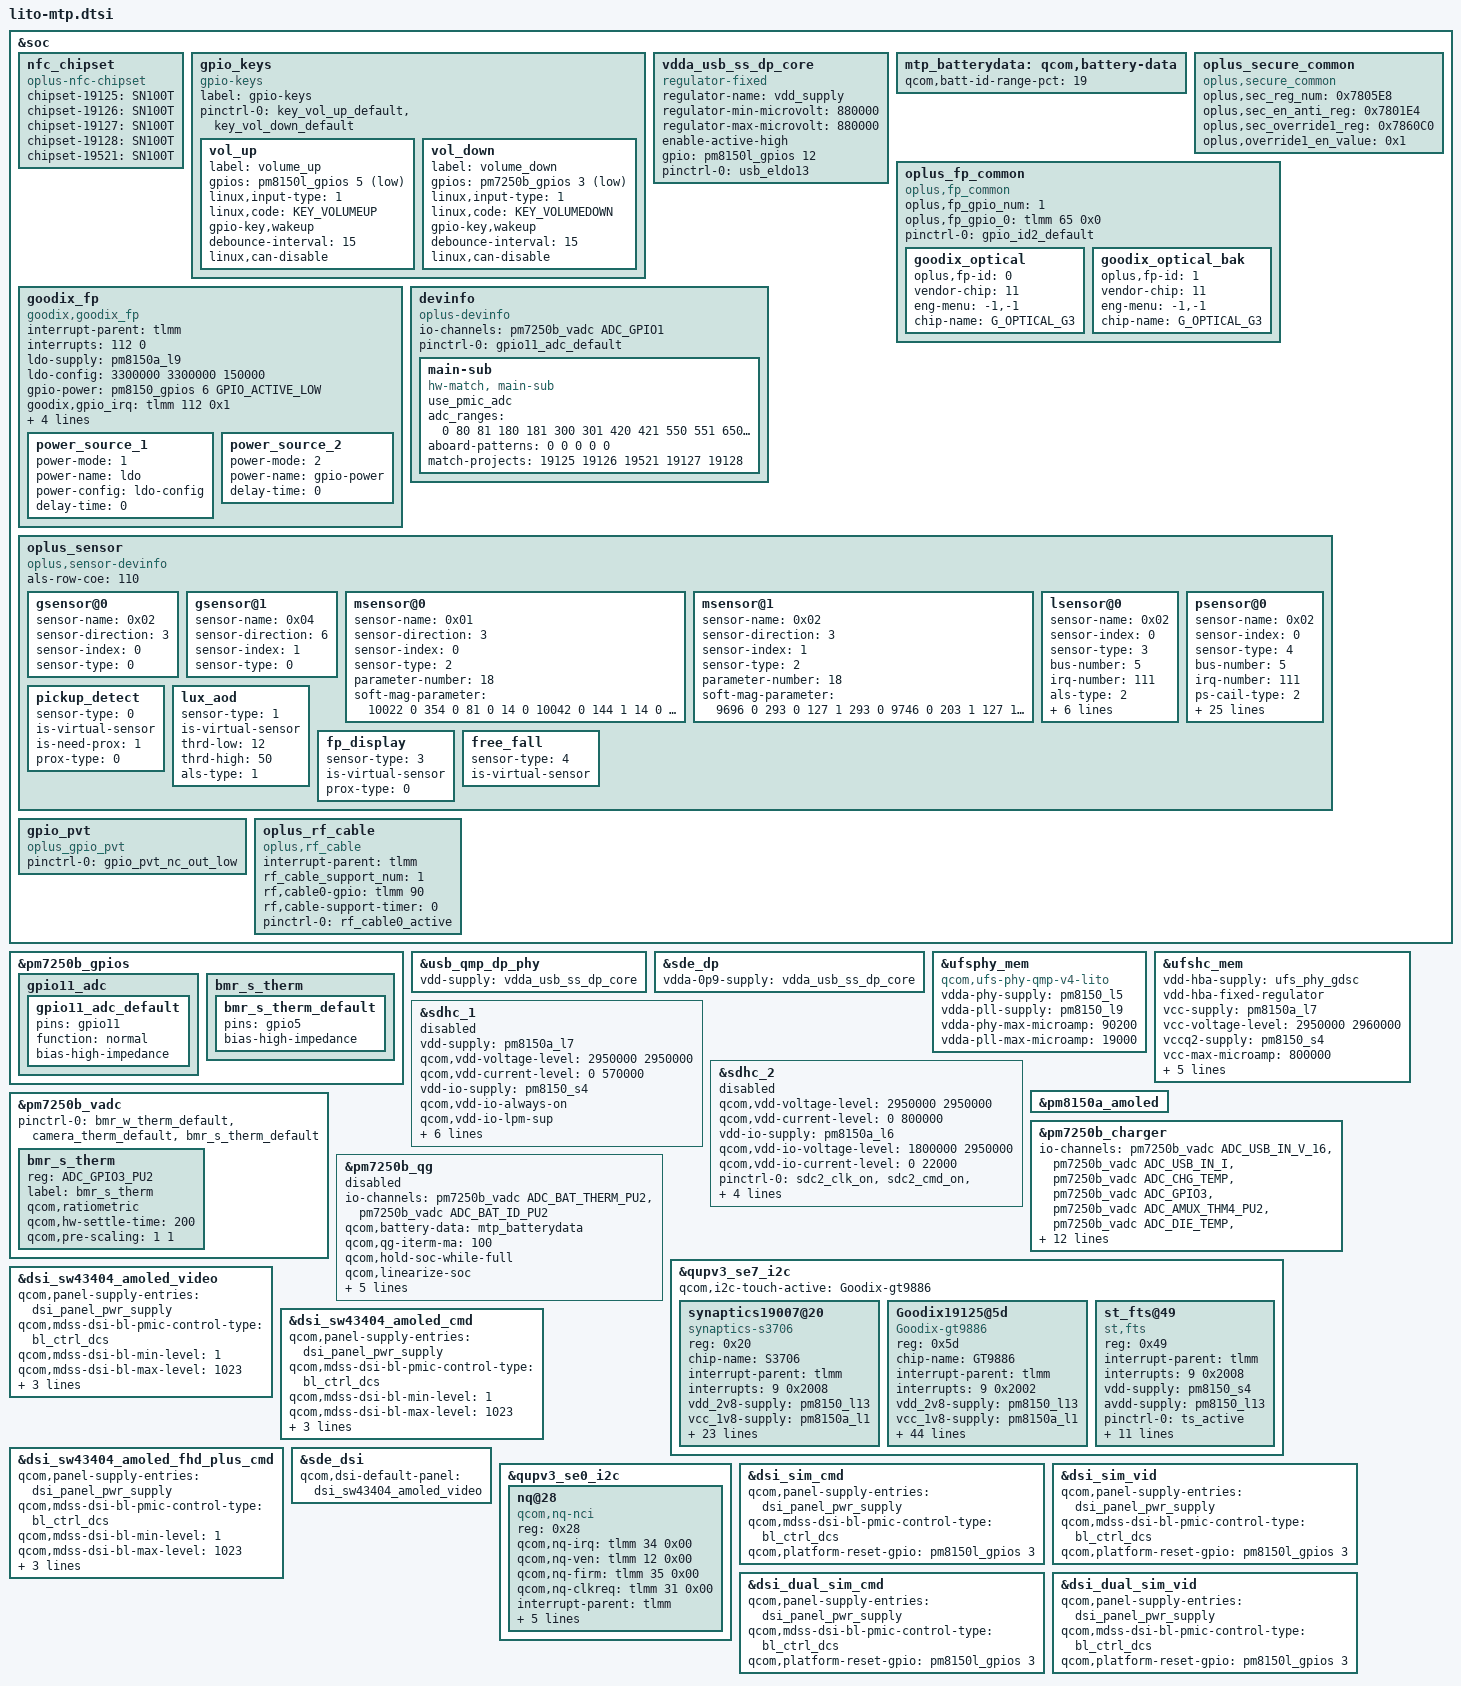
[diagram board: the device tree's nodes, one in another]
#include <dt-bindings/gpio/gpio.h>
#include "lito-audio-overlay.dtsi"
#include "lito-pmic-overlay.dtsi"
#include "camera/lito-camera-sensor-mtp.dtsi"
#include "lito-sde-display.dtsi"
#include "lito-thermal-overlay.dtsi"
#include "oplus_charge.dtsi"

&soc {
	//#ifdef OPLUS_FEATURE_CONNFCSOFT
	nfc_chipset {
		compatible = "oplus-nfc-chipset";
		chipset-19125 = "SN100T";
		chipset-19126 = "SN100T";
		chipset-19127 = "SN100T";
		chipset-19128 = "SN100T";
		chipset-19521 = "SN100T";
	};
	//#endif /* OPLUS_FEATURE_CONNFCSOFT */

	gpio_keys {
		compatible = "gpio-keys";
		label = "gpio-keys";

		pinctrl-names = "default";
		//#ifdef OPLUS_FEATURE_TP_BSPFWUPDATE
		pinctrl-0 = <&key_vol_up_default &key_vol_down_default>;
		//#endif

		vol_up {
			label = "volume_up";
			gpios = <&pm8150l_gpios 5 GPIO_ACTIVE_LOW>;
			linux,input-type = <1>;
			linux,code = <KEY_VOLUMEUP>;
			gpio-key,wakeup;
			debounce-interval = <15>;
			linux,can-disable;
		};
		//#ifdef OPLUS_FEATURE_TP_BSPFWUPDATE
		vol_down {
			label = "volume_down";
			gpios = <&pm7250b_gpios  3 GPIO_ACTIVE_LOW>;
			linux,input-type = <1>;
			linux,code = <KEY_VOLUMEDOWN>;
			gpio-key,wakeup;
			debounce-interval = <15>;
			linux,can-disable;
		};
		//#endif
	};

	vdda_usb_ss_dp_core: vdda_usb_ss_dp_core {
		compatible = "regulator-fixed";
		regulator-name = "vdd_supply";
		regulator-min-microvolt = <880000>;
		regulator-max-microvolt = <880000>;
		enable-active-high;
		gpio = <&pm8150l_gpios 12 GPIO_ACTIVE_HIGH>;
		pinctrl-names = "default";
		pinctrl-0 = <&usb_eldo13>;
	};

	mtp_batterydata: qcom,battery-data {
//#ifndef OPLUS_FEATURE_CHG_BASIC
//		qcom,batt-id-range-pct = <15>;
//#else
        qcom,batt-id-range-pct = <19>;
//#endif
		#include "qg-batterydata-alium-3600mah.dtsi"
		#include "qg-batterydata-atl466271_3300mAh.dtsi"
	};

	// #ifdef OPLUS_FEATURE_SECURITY_COMMON
	oplus_secure_common {
		compatible = "oplus,secure_common";
		oplus,sec_reg_num = <0x7805E8>;
		oplus,sec_en_anti_reg = <0x7801E4>;
		oplus,sec_override1_reg = <0x7860C0>;
		oplus,override1_en_value = <0x1>;
	};
	//#endif /* OPLUS_FEATURE_SECURITY_COMMON */

	//#ifdef OPLUS_FEATURE_FINGERPRINT
	oplus_fp_common {
		compatible = "oplus,fp_common";
		oplus,fp_gpio_num = <1>; /* the gpio number of fingerprint id used */
		oplus,fp_gpio_0 = <&tlmm 65 0x0>;
		pinctrl-names = "default";
		pinctrl-0 = <&gpio_id2_default>;
		goodix_optical {
			oplus,fp-id = <0>; /* fp id mapping table */
			vendor-chip = <11>; /* please refer to the struct fp_vendor_t in oplus_fp_commmon.n */
			eng-menu = "-1,-1"; /* represents SNR, inclination test item in engineer menu, and 0/1 means off/on */
			chip-name = "G_OPTICAL_G3";  /* /proc/fp_id, will be displayed in engineer menu  */
		};
		goodix_optical_bak {
			oplus,fp-id = <1>; /* fp id mapping table */
			vendor-chip = <11>; /* please refer to the struct fp_vendor_t in oplus_fp_commmon.n */
			eng-menu = "-1,-1"; /* represents SNR, inclination test item in engineer menu, and 0/1 means off/on */
			chip-name = "G_OPTICAL_G3";  /* /proc/fp_id, will be displayed in engineer menu  */
		};
	};

	goodix_fp {
		status = "ok";
		compatible = "goodix,goodix_fp";
		interrupt-parent = <&tlmm>;
		interrupts = <112 0>;

		ldo-supply = <&pm8150a_l9>; // pm660l_l5 for goodix_fp
		ldo-config = <3300000 3300000 150000>;

		gpio-power = <&pm8150_gpios 6 GPIO_ACTIVE_LOW>;
		goodix,gpio_irq = <&tlmm 112 0x1>;
		goodix,gpio_reset = <&tlmm 63 0x0>;
		pinctrl-names = "default";
		pinctrl-0 = <&gpio_goodix_irq_default>;
		pinctrl-1 = <&goodix_pwr_default>;

		power-num = <2> ;
		power_source_1 {
			power-mode = <1>;   /* 1 = ldo power, refer to oplus_fp_common.h*/
			power-name = "ldo";
			power-config = "ldo-config";
			delay-time = <0>;
		};
		power_source_2 {
			power-mode = <2>;   /* 2 = gpio power, refer to oplus_fp_common.h */
			power-name = "gpio-power";
			delay-time = <0>;
		};
	};
	//#endif /*OPLUS_FEATURE_FINGERPRINT*/

//#ifdef OPLUS_ARCH_EXTENDS
	devinfo {
	compatible = "oplus-devinfo";

	io-channels= <&pm7250b_vadc ADC_GPIO1>;
	io-channel-names= "vph_pwr_voltage_sub";
	pinctrl-names = "default";
	pinctrl-0 = <&gpio11_adc_default>;

	main-sub {
		compatible = "hw-match, main-sub";
		use_pmic_adc;
		adc_ranges = <0 80
					81 180
					181 300
					301 420
					421 550
					551 650
					651 760
					761 850
					851 850
					951 1050
					1051 1150
					1151 1300>;
		aboard-patterns = <0 0 0 0 0>;

		/*main board*/
		match-projects = <19125 19126 19521 19127 19128>;
		};
	};
//#endif /*OPLUS_ARCH_EXTENDS*/

	//#ifdef OPLUS_FEATURE_SENSOR_SMEM
	/*enum sensor_id { ACCEL,GYRO,MAG,LIGHT,PROXIMITY,SAR,CT,BAROMETER,SENSORS_NUM};*/
	oplus_sensor {
		compatible = "oplus,sensor-devinfo";
		als-row-coe = <110>;
		/*enum {LSM6DSM = 0x01, BMI160 = 0x02, LSM6DS3 = 0x04};*/
		gsensor@0 {
			sensor-name = <0x02>;//BMI160
			sensor-direction = <3>;
			sensor-index = <0>;//source num
			sensor-type = <0>;//ACCEL
		};
		gsensor@1 {
			sensor-name = <0x04>;//LSM6DS3
			sensor-direction = <6>;
			sensor-index = <1>;//source num
			sensor-type = <0>;//ACCEL
		};
		/* enum {AKM0991X = 0x01, MMC5603 = 0x02};*/
		msensor@0 {
			sensor-name = <0x01>;//AKM09918
			sensor-direction = <3>;
			sensor-index = <0>;
			sensor-type = <2>;//MAG
			parameter-number= <18>;
			soft-mag-parameter = <10022 0 354 0 81 0 14 0 10042 0 144 1 14 0 234 1 10250 0>;//e00 sign e01 sign...
		};
		msensor@1 {
			sensor-name = <0x02>;//MMC5603
			sensor-direction = <3>;
			sensor-index = <1>;
			sensor-type = <2>;//MAG
			parameter-number= <18>;
			soft-mag-parameter = <9696 0 293 0 127 1 293 0 9746 0 203 1 127 1 203 1 10600 0>;//e00 sign e01 sign...
		};
		/*enum {STK3A5X=0x01,TCS3701=0x02,TCS3408=0x04,STK3A6X=0x08};*/
		/*enum {NORMAL=0x01,UNDER_LCD=0x02,VIRTUAL_UNDER_LCD=0x03}*/
		lsensor@0 {
			sensor-name = <0x02>;//TCS3701
			sensor-index = <0>;
			sensor-type = <3>;//LIGHT
			bus-number = <5>;
			irq-number = <111>;
			als-type = <2>;
			is-unit-device = <1>;
			is-als-dri = <1>;
			als-factor = <110>;
			is_als_initialed = <0>;
			als_buffer_length = <10>;
			normalization_value = <549>;
		};
		psensor@0 {
			sensor-name = <0x02>;//TCS3701
			sensor-index = <0>;
			sensor-type = <4>;//PROXIMITY
			bus-number = <5>;
			irq-number = <111>;
			ps-cail-type = <2>;
			ps-type = <1>;
			is_ps_initialzed = <0>;
			low_step = <300>;//ps_low_thd_incr
			high_step = <400>;//ps_high_thd_incr
			low_limit = <400>;//ps_low_thd_max
			high_limit = <600>;//ps_high_thd_max
			dirty_low_step = <180>;//dirty_low_thd_incr
			dirty_high_step = <250>;//dirty_high_thd_incr
			ps_dirty_limit = <1022>;//dirty_limit
			ps_ir_limit = <500>;//ir_jam_limit
			ps_adjust_min = <0>;//ps_adjust_min
			ps_adjust_max = <600>;//ps_adjust_max
			sampling_count = <5>;//sampling_count
			step_max = <400>;//incr_max
			step_min = <110>;//incr_min
			step_div = <1500>;//cali_div
			anti_shake_delta = <80>;//delta
			dynamic_cali_max = <1024>;//dynamic_cali_max
			raw2offset_radio = <20800>;//raw_to_offser_radio
			offset_max = <250>;//max_offset
			offset_range_min = <0xFFFFFF01>;//-255
			offset_range_max = <255>;
			force_cali_limit = <2000>;
			cali_jitter_limit = <30>;//dynamic_cali_value
			cal_offset_margin = <120>;//cal_offset_margin
		};
		/*virtual sensor
		enum sensor_algo_id {
			PICKUP_DETECT,
			LUX_AOD,
			TP_GESTURE,
			FP_DISPLAY,
			FREE_FALL,
			CAMERA_PROTECT,
			SENSOR_ALGO_NUM
		}*/
		pickup_detect {
			sensor-type = <0>; //PICKUP_DETECT
			is-virtual-sensor;
			is-need-prox = <1>;
			prox-type = <0>; // 0 - proximity; 1 - proximity_fake
		};
		lux_aod {
			sensor-type = <1>; //LUX_AOD
			is-virtual-sensor;
			thrd-low = <12>;
			thrd-high = <50>;
			als-type = <1>; // 0 - ambient_light; 1 - wise_light
		};
		fp_display {
			sensor-type = <3>; //FP_DISPLAY
			is-virtual-sensor;
			prox-type = <0>; // 0 - proximity; 1 - proximity_fake
		};
		free_fall {
			sensor-type = <4>; //FREE_FALL
			is-virtual-sensor;
		};
	};
	//#endif /*OPLUS_FEATURE_SENSOR_SMEM*/

	gpio_pvt {
		status = "ok";
		compatible = "oplus_gpio_pvt";
		pinctrl-names = "default";
		pinctrl-0 = <&gpio_pvt_nc_out_low>;
	};
	//#endif

        //#ifdef OPLUS_ARCH_EXTENDS
	oplus_rf_cable {
		compatible = "oplus,rf_cable";
		interrupt-parent = <&tlmm>;
		rf_cable_support_num = <1>;
		rf,cable0-gpio = <&tlmm 90 0>;
		rf,cable-support-timer = <0>;
		pinctrl-names = "rf_cable_active";
		pinctrl-0 = <&rf_cable0_active>;
	};
	//#endif /* OPLUS_ARCH_EXTENDS */
};

//#ifndef OPLUS_FEATURE_CHG_BASIC
//&usb2_phy0 {
//	qcom,param-override-seq = <0xa1 0x6c
//				0x43 0x70>;
//};
//#endif
//#ifdef OPLUS_FEATURE_CHG_BASIC
&pm7250b_gpios{
	gpio11_adc {
        gpio11_adc_default: gpio11_adc_default {
        pins = "gpio11"; /* GPIO 11 */
        function = "normal"; /* normal */
        bias-high-impedance; /* DISABLE GPIO11 for ADC*/
        };
    };
};
//#endif

&usb_qmp_dp_phy {
	vdd-supply = <&vdda_usb_ss_dp_core>;
};

&sde_dp {
	vdda-0p9-supply = <&vdda_usb_ss_dp_core>;
};

&ufsphy_mem {
	compatible = "qcom,ufs-phy-qmp-v4-lito";

	vdda-phy-supply = <&pm8150_l5>;
	vdda-pll-supply = <&pm8150_l9>;
	vdda-phy-max-microamp = <90200>;
	vdda-pll-max-microamp = <19000>;

	status = "ok";
};

&ufshc_mem {
	vdd-hba-supply = <&ufs_phy_gdsc>;
	vdd-hba-fixed-regulator;
	vcc-supply = <&pm8150a_l7>;
	vcc-voltage-level = <2950000 2960000>;
	vccq2-supply = <&pm8150_s4>;
	vcc-max-microamp = <800000>;
	vccq2-max-microamp = <800000>;

	qcom,vddp-ref-clk-supply = <&pm8150_l9>;
	qcom,vddp-ref-clk-max-microamp = <100>;
	qcom,vddp-ref-clk-min-uV = <1152000>;
	qcom,vddp-ref-clk-max-uV = <1200000>;
	status = "ok";
};

&sdhc_1 {
	vdd-supply = <&pm8150a_l7>;
	qcom,vdd-voltage-level = <2950000 2950000>;
	qcom,vdd-current-level = <0 570000>;

	vdd-io-supply = <&pm8150_s4>;
	qcom,vdd-io-always-on;
	qcom,vdd-io-lpm-sup;
	qcom,vdd-io-voltage-level = <1800000 1800000>;
	qcom,vdd-io-current-level = <0 325000>;

	pinctrl-names = "active", "sleep";
	pinctrl-0 = <&sdc1_clk_on &sdc1_cmd_on &sdc1_data_on
					&sdc1_rclk_on>;
	pinctrl-1 = <&sdc1_clk_off &sdc1_cmd_off &sdc1_data_off
					&sdc1_rclk_off>;

	status = "disabled";
};

&sdhc_2 {
/* #ifndef OPLUS_FEATURE_FINGERPRINT */
/* vdd-supply = <&pm8150a_l9>;*/
/* #endif VENDOR_EDIT */
	qcom,vdd-voltage-level = <2950000 2950000>;
	qcom,vdd-current-level = <0 800000>;

	vdd-io-supply = <&pm8150a_l6>;
	qcom,vdd-io-voltage-level = <1800000 2950000>;
	qcom,vdd-io-current-level = <0 22000>;

	pinctrl-names = "active", "sleep";
	pinctrl-0 = <&sdc2_clk_on  &sdc2_cmd_on &sdc2_data_on &sdc2_cd_on>;
	pinctrl-1 = <&sdc2_clk_off &sdc2_cmd_off &sdc2_data_off &sdc2_cd_off>;

	cd-gpios = <&tlmm 69 GPIO_ACTIVE_LOW>;

	status = "disabled";
};

&pm8150a_amoled {
	status = "ok";
};

&pm7250b_vadc {
	pinctrl-0 = <
		&bmr_w_therm_default
		&camera_therm_default
		&bmr_s_therm_default
	>;

	bmr_s_therm {
		reg = <ADC_GPIO3_PU2>;
		label = "bmr_s_therm";
		qcom,ratiometric;
		qcom,hw-settle-time = <200>;
		qcom,pre-scaling = <1 1>;
	};
};

&pm7250b_gpios {
	bmr_s_therm {
		bmr_s_therm_default: bmr_s_therm_default {
			pins = "gpio5";
			bias-high-impedance;
		};
	};
};

/*
&pm7250b_adc_tm {
	io-channels = <&pm7250b_vadc ADC_AMUX_THM1_PU2>,
			<&pm7250b_vadc ADC_GPIO2_PU2>,
			<&pm7250b_vadc ADC_GPIO3_PU2>,
			<&pm7250b_vadc ADC_GPIO4_PU2>;

	bmr_s_therm@54 {
		reg = <ADC_GPIO3_PU2>;
		qcom,ratiometric;
		qcom,hw-settle-time = <200>;
	};
};

&thermal_zones {
	mmw-pa4-usr {
		polling-delay-passive = <0>;
		polling-delay = <0>;
		thermal-governor = "user_space";
		thermal-sensors = <&pm7250b_adc_tm ADC_GPIO3_PU2>;
		wake-capable-sensor;
		trips {
			active-config0 {
				temperature = <125000>;
				hysteresis = <1000>;
				type = "passive";
			};
		};
	};
};
*/

&pm7250b_charger {
	status = "ok";
	io-channels = <&pm7250b_vadc ADC_USB_IN_V_16>,
		      <&pm7250b_vadc ADC_USB_IN_I>,
		      <&pm7250b_vadc ADC_CHG_TEMP>,
			  <&pm7250b_vadc ADC_GPIO3>,
			  <&pm7250b_vadc ADC_AMUX_THM4_PU2>,
//#endif
		      <&pm7250b_vadc ADC_DIE_TEMP>,
		      <&pm7250b_vadc ADC_AMUX_THM3_PU2>,
		      <&pm7250b_vadc ADC_SBUx>,
		      <&pm7250b_vadc ADC_VPH_PWR>,
		      <&pm7250b_vadc ADC_AMUX_THM1_PU2>;
	io-channel-names = "usb_in_voltage",
			   "usb_in_current",
			   "chg_temp",
			   "chgID_voltage_adc",
			   "usb_temp_l",
//#endif
			   "die_temp",
			   "usb_temp_r",
//#else
			   //"conn_temp",
//#endif
			   "sbux_res",
			   "vph_voltage",
			   "skin_temp";
	qcom,battery-data = <&mtp_batterydata>;
	//qcom,sec-charger-config = <1>;
	//qcom,auto-recharge-soc = <98>;
	//qcom,step-charging-enable;
	//qcom,sw-jeita-enable;
//#endif
	qcom,charger-temp-max = <800>;
	qcom,smb-temp-max = <800>;
	//qcom,suspend-input-on-debug-batt;
	//qcom,fcc-stepping-enable;
//#endif
	qcom,fcc-step-delay-ms = <100>;
	qcom,fcc-step-size-ua = <100000>;
	qcom,smb-internal-pull-kohm = <0>;
	qcom,en-skin-therm-mitigation;
	qcom,hvdcp3-standalone-config;
};

&pm7250b_qg {
	status = "disabled";
//#else
	//status = "ok";
//#endif
	io-channels = <&pm7250b_vadc ADC_BAT_THERM_PU2>,
		      <&pm7250b_vadc ADC_BAT_ID_PU2>;
	io-channel-names = "batt-therm",
			   "batt-id";
	qcom,battery-data = <&mtp_batterydata>;
	qcom,qg-iterm-ma = <100>;
	qcom,hold-soc-while-full;
	qcom,linearize-soc;
	qcom,cl-feedback-on;
	qcom,tcss-enable;
	qcom,fvss-enable;
	qcom,fvss-vbatt-mv = <3300>;
	qcom,bass-enable;
};

&qupv3_se7_i2c {
	#address-cells = <1>;
	#size-cells = <0>;

	status = "ok";
	qcom,i2c-touch-active = "Goodix-gt9886";
	//#ifdef OPLUS_FEATURE_TP_BASIC
	synaptics19007@20 {
		compatible = "synaptics-s3706";
		reg = <0x20>;
		chip-name = "S3706";

		/* Interrupt && Irq-gpio */
		interrupt-parent = <&tlmm>;
		interrupts = <9 0x2008>;

		/* Power Config */
		vdd_2v8-supply = <&pm8150_l13>;
		vcc_1v8-supply = <&pm8150a_l1>;
		vdd_2v8_volt = <3000000>;

		/* Other HW Resource */
		irq-gpio = <&tlmm 9 0x2008>;
		reset-gpio = <&tlmm 8 0x1>;
		pinctrl-names = "default";
		pinctrl-0 = <&ts_int_active &ts_reset_active>;

		touchpanel,max-num-support = <10>;
		touchpanel,tx-rx-num = <16 34>;
		touchpanel,panel-coords = <1080 2340>;
		touchpanel,display-coords = <1080 2340>;
		touchpanel,touchmajor-limit = <0 54>;

		/* SW Support Feature Control */
		black_gesture_support;
		fw_edge_limit_support;
		fw_corner_limit_support;
		pressure_report_support;
		//spurious_fingerprint_support;
		charger_pump_support;
		game_switch_support;
		face_detect_support;
		smart_gesture_support;
		fw_update_app_support;
		fingerprint_underscreen_support;
		rt155_fdreplace_rt59_support;
		report_120hz_support;
		/*
		 *Virtual Key Config:
		 *1:touchpanel,button-type: <virtualkey_type  supportted_button-map>
		 *virtualkey_type:
		 *Type 1: using board_properties
		 *Type 2: using same IC (button zone&& touch zone are seprate)
		 *Type 3: using diffrent IC (button zone&& touch zone are seprate)
		 *Type 4: No need of virtual key process
		 *supportted_button-map:select|menu|home|back
		 *
		 *2:touchpanel,button-map
		 *type (X1,Y1)(X2,Y2)(X3,Y3)(Width_X,Hight_Y)--Only when button-type is 0
		 */
		touchpanel,button-type = <4>;
		touchpanel.button-TRx = <0 0>;
	};
	//#endif /*OPLUS_FEATURE_TP_BASIC*/

	//#ifdef OPLUS_FEATURE_TP_BASIC
	Goodix19125@5d {
		compatible = "Goodix-gt9886";
		reg = <0x5d>;
		chip-name = "GT9886";

		/* Interrupt && Irq-gpio */
		interrupt-parent = <&tlmm>;
		interrupts = <9 0x2002>;

		/* Power Config */
		vdd_2v8-supply = <&pm8150_l13>;
		vcc_1v8-supply = <&pm8150a_l1>;
		vdd_2v8_volt = <3100000>;

		/* Other HW Resource */
		irq-gpio = <&tlmm 9 0x2002>;
		reset-gpio = <&tlmm 8 0x1>;
		pinctrl-names = "default";
		pinctrl-0 = <&ts_int_active &ts_reset_active>;

		vid_len = <0>;
		tp_type = <8>;
		// type of tp_dev ,TP-SAMSUNG = 8;
		platform_support_project = <19125 19126 19127 19128 19521 19522>;
		platform_support_project_dir = <19125 19125 19125 19125 19125 19125>;
		platform_support_project_commandline = "default_commandline", "default_commandline", "default_commandline", "default_commandline", "default_commandline", "default_commandline";

		touchpanel,max-num-support = <10>;
		touchpanel,tx-rx-num = <15 34>;
		touchpanel,panel-coords = <1080 2400>;
		touchpanel,display-coords = <1080 2400>;
		touchpanel,touchmajor-limit = <0 54>;
		prevention,dead_area_width = <10 10>;
		prevention,makeup_cnt_weight = <4 1 2 2 1>;
		prevention,large_judge_para = <1 320 300>;
		prevention,large_corner_judge_para = <30 3 3 45 45 0>;
		prevention,condition_judge_para = <40 30>;
		prevention,condition_area_width = <30 30 80 80>;
		prevention,large_area_width = <120 120>;
		prevention,large_corner_width = <60 400 120>;
		prevention,eli_area_width = <120 500 600 120>;
		prevention,grip_disable_level = <4>;

		/* SW Support Feature Control */
		register-is-16bit;
		black_gesture_support;
		//fw_edge_limit_support;
		pressure_report_support;
		charger_pump_support;
		game_switch_support;
		smart_gesture_support;
		fw_update_app_support;
		fingerprint_underscreen_support;
		esd_handle_support;
		new_set_irq_wake_support;
		single_tap_support;
		kernel_grip_support;
		/*
		 *Virtual Key Config:
		 *1:touchpanel,button-type: <virtualkey_type  supportted_button-map>
		 *virtualkey_type:
		 *Type 1: using board_properties
		 *Type 2: using same IC (button zone&& touch zone are seprate)
		 *Type 3: using diffrent IC (button zone&& touch zone are seprate)
		 *Type 4: No need of virtual key process
		 *supportted_button-map:select|menu|home|back
		 *
		 *2:touchpanel,button-map
		 *type (X1,Y1)(X2,Y2)(X3,Y3)(Width_X,Hight_Y)--Only when button-type is 0
		 */
		touchpanel,button-type = <4>;
		touchpanel.button-TRx = <0 0>;
	};
	//#endif  /*OPLUS_FEATURE_TP_BASIC*/

	st_fts@49 {
		compatible = "st,fts";
		reg = <0x49>;
		interrupt-parent = <&tlmm>;
		interrupts = <9 0x2008>;
		vdd-supply = <&pm8150_s4>;
		avdd-supply = <&pm8150_l13>;
		pinctrl-names = "pmx_ts_active", "pmx_ts_suspend";
		pinctrl-0 = <&ts_active>;
		pinctrl-1 = <&ts_int_suspend &ts_reset_suspend>;
		st,irq-gpio = <&tlmm 9 0x2008>;
		st,reset-gpio = <&tlmm 8 0x00>;
		st,regulator_dvdd = "vdd";
		st,regulator_avdd = "avdd";
		st,x-flip = <1>;
		st,y-flip = <1>;
		st,power_on_suspend;
		panel = <&dsi_sw43404_amoled_cmd &dsi_sw43404_amoled_video
			 &dsi_sw43404_amoled_fhd_plus_cmd>;
	};
};

&dsi_sw43404_amoled_video {
	qcom,panel-supply-entries = <&dsi_panel_pwr_supply>;
	qcom,mdss-dsi-bl-pmic-control-type = "bl_ctrl_dcs";
	qcom,mdss-dsi-bl-min-level = <1>;
	qcom,mdss-dsi-bl-max-level = <1023>;
	qcom,mdss-brightness-max-level = <255>;
	qcom,platform-te-gpio = <&tlmm 10 0>;
	qcom,platform-reset-gpio = <&pm8150l_gpios 3 0>;
};

&dsi_sw43404_amoled_cmd {
	qcom,panel-supply-entries = <&dsi_panel_pwr_supply>;
	qcom,mdss-dsi-bl-pmic-control-type = "bl_ctrl_dcs";
	qcom,mdss-dsi-bl-min-level = <1>;
	qcom,mdss-dsi-bl-max-level = <1023>;
	qcom,mdss-brightness-max-level = <255>;
	qcom,platform-te-gpio = <&tlmm 10 0>;
	qcom,platform-reset-gpio = <&pm8150l_gpios 3 0>;
};

&dsi_sw43404_amoled_fhd_plus_cmd {
	qcom,panel-supply-entries = <&dsi_panel_pwr_supply>;
	qcom,mdss-dsi-bl-pmic-control-type = "bl_ctrl_dcs";
	qcom,mdss-dsi-bl-min-level = <1>;
	qcom,mdss-dsi-bl-max-level = <1023>;
	qcom,mdss-brightness-max-level = <255>;
	qcom,platform-te-gpio = <&tlmm 10 0>;
	qcom,platform-reset-gpio = <&pm8150l_gpios 3 0>;
};

&sde_dsi {
	qcom,dsi-default-panel = <&dsi_sw43404_amoled_video>;
};

&qupv3_se0_i2c {
	status = "ok";
	//#ifndef VENDOR_EDIT
	//qcom,clk-freq-out = <1000000>;
	//#endif /* VENDOR_EDIT */
	#address-cells = <1>;
	#size-cells = <0>;
	nq@28 {
		compatible = "qcom,nq-nci";
		reg = <0x28>;
		qcom,nq-irq = <&tlmm 34 0x00>;
		qcom,nq-ven = <&tlmm 12 0x00>;
		qcom,nq-firm = <&tlmm 35 0x00>;
		qcom,nq-clkreq = <&tlmm 31 0x00>;
		interrupt-parent = <&tlmm>;
		interrupts = <34 0>;
		interrupt-names = "nfc_irq";
		pinctrl-names = "nfc_active", "nfc_suspend";
		pinctrl-0 = <&nfc_int_active &nfc_enable_active
				&nfc_clk_req_active>;
		pinctrl-1 = <&nfc_int_suspend &nfc_enable_suspend
				&nfc_clk_req_suspend>;
	};
};

&dsi_sim_cmd {
	qcom,panel-supply-entries = <&dsi_panel_pwr_supply>;
	qcom,mdss-dsi-bl-pmic-control-type = "bl_ctrl_dcs";
	qcom,platform-reset-gpio = <&pm8150l_gpios 3 0>;
};

&dsi_sim_vid {
	qcom,panel-supply-entries = <&dsi_panel_pwr_supply>;
	qcom,mdss-dsi-bl-pmic-control-type = "bl_ctrl_dcs";
	qcom,platform-reset-gpio = <&pm8150l_gpios 3 0>;
};

&dsi_dual_sim_cmd {
	qcom,panel-supply-entries = <&dsi_panel_pwr_supply>;
	qcom,mdss-dsi-bl-pmic-control-type = "bl_ctrl_dcs";
	qcom,platform-reset-gpio = <&pm8150l_gpios 3 0>;
};

&dsi_dual_sim_vid {
	qcom,panel-supply-entries = <&dsi_panel_pwr_supply>;
	qcom,mdss-dsi-bl-pmic-control-type = "bl_ctrl_dcs";
	qcom,platform-reset-gpio = <&pm8150l_gpios 3 0>;
};

